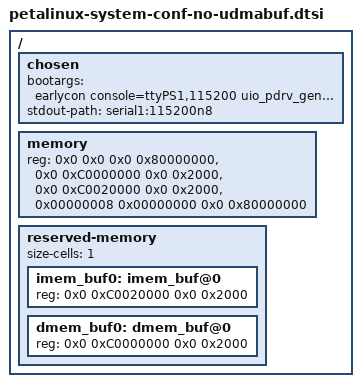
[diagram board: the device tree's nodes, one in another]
/include/ "system-conf.dtsi"
/ {
        chosen {
                bootargs = "earlycon console=ttyPS1,115200 uio_pdrv_genirq.of_id=generic-uio clk_ignore_unused init_fatal_sh=1 cma=900M ";
                stdout-path = "serial1:115200n8";
        };

        #address-cells = <1>;
        #size-cells = <1>;
        memory {
            device_type = "memory";
            reg = <0x0 0x0 0x0 0x80000000>, <0x0 0xC0000000 0x0 0x2000>, <0x0 0xC0020000 0x0 0x2000>, <0x00000008 0x00000000 0x0 0x80000000>;
        };
        reserved-memory {
            #address-cells = <1>;
            #  size-cells = <1>;
            ranges;

            imem_buf0: imem_buf@0 {
                reg = <0x0 0xC0020000 0x0 0x2000>;
            };

            dmem_buf0: dmem_buf@0 {
                reg = <0x0 0xC0000000 0x0 0x2000>;
            };
        };
};

